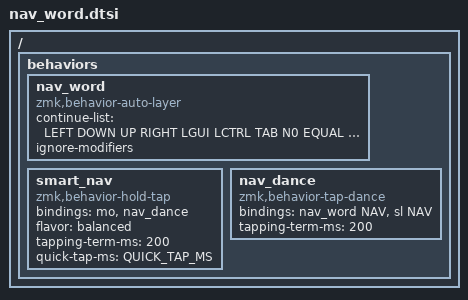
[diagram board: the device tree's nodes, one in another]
#include <dt-bindings/zmk/behaviors.h>
#include <dt-bindings/zmk/keys.h>

/ {
    behaviors {
        nav_word: nav_word {
            compatible = "zmk,behavior-auto-layer";
            #binding-cells = <1>;
            continue-list = <LEFT DOWN UP RIGHT LGUI LCTRL TAB N0 EQUAL MINUS DEL BSPC>;
            ignore-modifiers;
        };
    };
};

// Tap: nav-word | double-tap: sticky nav-layer | Hold: nav-layer.
#define SMART_NAV &smart_nav NAV NAV
ZMK_HOLD_TAP(smart_nav, bindings = <&mo>, <&nav_dance>; flavor = "balanced";
             tapping-term-ms = <200>; quick-tap-ms = <QUICK_TAP_MS>;)
ZMK_TAP_DANCE(nav_dance, bindings = <&nav_word NAV>, <&sl NAV>;
              tapping-term-ms = <200>;)
